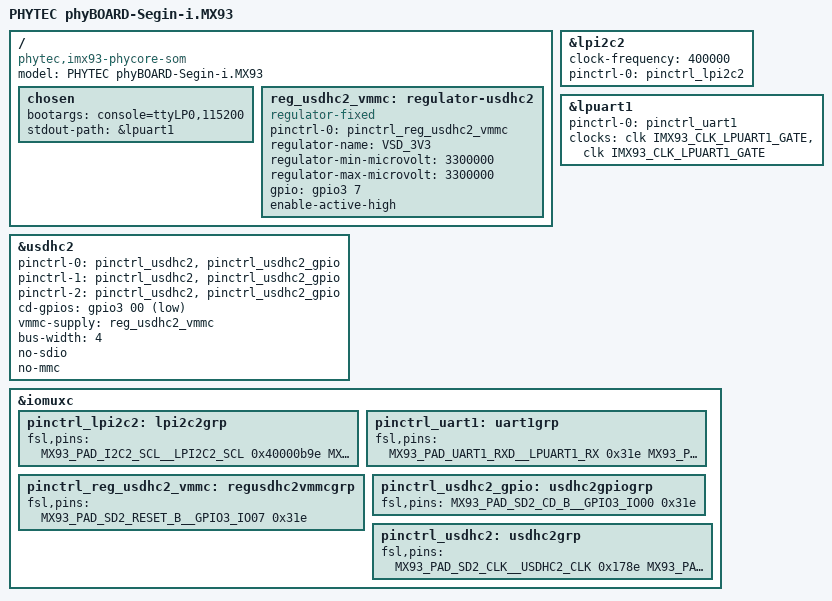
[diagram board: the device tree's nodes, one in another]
// SPDX-License-Identifier: (GPL-2.0+ OR MIT)
/*
 * Copyright (C) 2023 PHYTEC Messtechnik GmbH
 * Christoph Stoidner <c.stoidner@phytec.de>
 *
 * Product homepage:
 * phyBOARD-Segin carrier board is reused for the i.MX93 design.
 * https://www.phytec.de/produkte/single-board-computer/phyboard-segin-imx6ul/
 */
/dts-v1/;

#include "phycore-imx93-som.dtsi"

/{
	model = "PHYTEC phyBOARD-Segin-i.MX93";
	compatible = "phytec,imx93-phycore-som", "fsl,imx93";

	chosen {
		bootargs = "console=ttyLP0,115200";
		stdout-path = &lpuart1;
	};

	reg_usdhc2_vmmc: regulator-usdhc2 {
		compatible = "regulator-fixed";
		pinctrl-names = "default";
		pinctrl-0 = <&pinctrl_reg_usdhc2_vmmc>;
		regulator-name = "VSD_3V3";
		regulator-min-microvolt = <3300000>;
		regulator-max-microvolt = <3300000>;
		gpio = <&gpio3 7 GPIO_ACTIVE_HIGH>;
		enable-active-high;
	};
};

&lpi2c2 {
	clock-frequency = <400000>;
	pinctrl-names = "default";
	pinctrl-0 = <&pinctrl_lpi2c2>;
	#address-cells = <1>;
	#size-cells = <0>;
	status = "okay";
};

/* Console */
&lpuart1 {
	pinctrl-names = "default";
	pinctrl-0 = <&pinctrl_uart1>;
	clocks = <&clk IMX93_CLK_LPUART1_GATE>, <&clk IMX93_CLK_LPUART1_GATE>;
	clock-names = "ipg", "per";
	status = "okay";
};

/* SD-Card */
&usdhc2 {
	pinctrl-names = "default", "state_100mhz", "state_200mhz";
	/*
	 * Need to set those pinctrl states, although all pinctrls are
	 * the same. That is needed to tell driver to enable those
	 * different UHS modes.
	 */
	pinctrl-0 = <&pinctrl_usdhc2>, <&pinctrl_usdhc2_gpio>;
	pinctrl-1 = <&pinctrl_usdhc2>, <&pinctrl_usdhc2_gpio>;
	pinctrl-2 = <&pinctrl_usdhc2>, <&pinctrl_usdhc2_gpio>;
	cd-gpios = <&gpio3 00 GPIO_ACTIVE_LOW>;
	vmmc-supply = <&reg_usdhc2_vmmc>;
	bus-width = <4>;
	no-sdio;
	no-mmc;
	status = "okay";
};

&iomuxc {
	pinctrl-names = "default";
	status = "okay";

	pinctrl_lpi2c2: lpi2c2grp {
		fsl,pins = <
			MX93_PAD_I2C2_SCL__LPI2C2_SCL			0x40000b9e
			MX93_PAD_I2C2_SDA__LPI2C2_SDA			0x40000b9e
		>;
	};

	pinctrl_uart1: uart1grp {
		fsl,pins = <
			MX93_PAD_UART1_RXD__LPUART1_RX			0x31e
			MX93_PAD_UART1_TXD__LPUART1_TX			0x31e
		>;
	};

	pinctrl_reg_usdhc2_vmmc: regusdhc2vmmcgrp {
		fsl,pins = <
			MX93_PAD_SD2_RESET_B__GPIO3_IO07		0x31e
		>;
	};

	pinctrl_usdhc2_gpio: usdhc2gpiogrp {
		fsl,pins = <
			MX93_PAD_SD2_CD_B__GPIO3_IO00			0x31e
		>;
	};

	pinctrl_usdhc2: usdhc2grp {
		fsl,pins = <
			MX93_PAD_SD2_CLK__USDHC2_CLK			0x178e
			MX93_PAD_SD2_CMD__USDHC2_CMD			0x139e
			MX93_PAD_SD2_DATA0__USDHC2_DATA0		0x138e
			MX93_PAD_SD2_DATA1__USDHC2_DATA1		0x138e
			MX93_PAD_SD2_DATA2__USDHC2_DATA2		0x138e
			MX93_PAD_SD2_DATA3__USDHC2_DATA3		0x139e
			MX93_PAD_SD2_VSELECT__USDHC2_VSELECT		0x51e
		>;
	};
};
